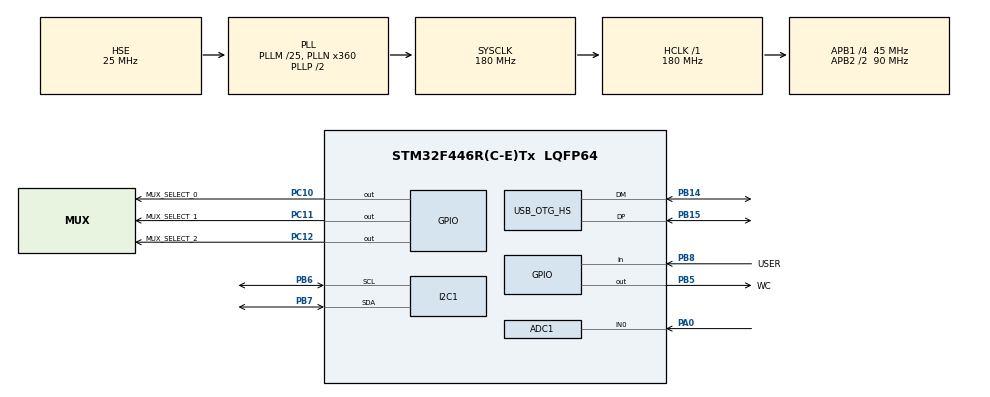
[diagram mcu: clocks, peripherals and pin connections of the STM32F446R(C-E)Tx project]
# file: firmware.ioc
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ADC1.Channel-0\#ChannelRegularConversion=ADC_CHANNEL_0
ADC1.NbrOfConversionFlag=1
ADC1.Rank-0\#ChannelRegularConversion=1
ADC1.SamplingTime-0\#ChannelRegularConversion=ADC_SAMPLETIME_3CYCLES
ADC1.master=1
Mcu.Family=STM32F4
Mcu.Name=STM32F446R(C-E)Tx
Mcu.Package=LQFP64
NVIC.ADC_IRQn=true\:0\:0\:false\:false\:true\:true\:true\:true
NVIC.OTG_HS_IRQn=true\:0\:0\:false\:false\:true\:true\:true\:true
NVIC.PriorityGroup=NVIC_PRIORITYGROUP_4
NVIC.TIM1_UP_TIM10_IRQn=true\:0\:0\:false\:false\:true\:true\:true\:true
PA0-WKUP.Signal=ADCx_IN0
PA13.Mode=Trace_Asynchronous_SW
PA13.Signal=SYS_JTMS-SWDIO
PA14.Mode=Trace_Asynchronous_SW
PA14.Signal=SYS_JTCK-SWCLK
PB14.Mode=Device_Only_FS
PB14.Signal=USB_OTG_HS_DM
PB15.Mode=Device_Only_FS
PB15.Signal=USB_OTG_HS_DP
PB3.Mode=Trace_Asynchronous_SW
PB3.Signal=SYS_JTDO-SWO
PB5.GPIO_Label=WC
PB5.GPIO_Speed=GPIO_SPEED_FREQ_HIGH
PB5.Signal=GPIO_Output
PB6.Mode=I2C
PB6.Signal=I2C1_SCL
PB7.Mode=I2C
PB7.Signal=I2C1_SDA
PB8.GPIO_Label=USER
PB8.Signal=GPIO_Input
PC10.GPIO_Label=MUX_SELECT_0
PC10.GPIO_Speed=GPIO_SPEED_FREQ_VERY_HIGH
PC10.Signal=GPIO_Output
PC11.GPIO_Label=MUX_SELECT_1
PC11.GPIO_Speed=GPIO_SPEED_FREQ_VERY_HIGH
PC11.Signal=GPIO_Output
PC12.GPIO_Label=MUX_SELECT_2
PC12.GPIO_Speed=GPIO_SPEED_FREQ_VERY_HIGH
PC12.Signal=GPIO_Output
PH0-OSC_IN.Mode=HSE-External-Oscillator
PH0-OSC_IN.Signal=RCC_OSC_IN
PH1-OSC_OUT.Mode=HSE-External-Oscillator
PH1-OSC_OUT.Signal=RCC_OSC_OUT
ProjectManager.HeapSize=0x200
ProjectManager.StackSize=0x400
ProjectManager.TargetToolchain=STM32CubeIDE
RCC.AHBFreq_Value=180000000
RCC.APB1CLKDivider=RCC_HCLK_DIV4
RCC.APB1Freq_Value=45000000
RCC.APB1TimFreq_Value=90000000
RCC.APB2CLKDivider=RCC_HCLK_DIV2
RCC.APB2Freq_Value=90000000
RCC.APB2TimFreq_Value=180000000
RCC.CortexFreq_Value=180000000
RCC.HCLKFreq_Value=180000000
RCC.PLLM=25
RCC.PLLN=360
RCC.PLLSAIM=25
RCC.PLLSAIP=RCC_PLLSAIP_DIV4
RCC.PLLSourceVirtual=RCC_PLLSOURCE_HSE
RCC.SYSCLKFreq_VALUE=180000000
RCC.SYSCLKSource=RCC_SYSCLKSOURCE_PLLCLK
RCC.USBCLockSelection=RCC_CLK48CLKSOURCE_PLLSAIP
RCC.USBFreq_Value=48000000
RCC.VCOOutputFreq_Value=360000000
SH.ADCx_IN0.0=ADC1_IN0,IN0
TIM10.Period=3600 - 1
TIM10.Prescaler=0
USB_OTG_HS.VirtualMode-Device_Only_FS=Device_Only_FS
VP_TIM10_VS_ClockSourceINT.Mode=Enable_Timer
board=custom

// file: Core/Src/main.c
/* USER CODE BEGIN Header */
/**
 ******************************************************************************
 * @file           : main.c
 * @brief          : Main program body
 ******************************************************************************
 * @attention
 *
 * Copyright (c) 2024 STMicroelectronics.
 * All rights reserved.
 *
 * This software is licensed under terms that can be found in the LICENSE file
 * in the root directory of this software component.
 * If no LICENSE file comes with this software, it is provided AS-IS.
 *
 ******************************************************************************
 */
/* USER CODE END Header */
#include "main.h"

/* USER CODE BEGIN Includes */

#include "firmware.h"

/* USER CODE END Includes */

ADC_HandleTypeDef hadc1;

I2C_HandleTypeDef hi2c1;

TIM_HandleTypeDef htim10;

PCD_HandleTypeDef hpcd_USB_OTG_HS;

void SystemClock_Config(void);
static void MX_GPIO_Init(void);
static void MX_ADC1_Init(void);
static void MX_I2C1_Init(void);
static void MX_TIM10_Init(void);
static void MX_USB_OTG_HS_PCD_Init(void);

int main(void) {

  /* MCU Configuration--------------------------------------------------------*/

  /* Reset of all peripherals, Initializes the Flash interface and the Systick.
   */
  HAL_Init();

  /* Configure the system clock */
  SystemClock_Config();

  /* Initialize all configured peripherals */
  MX_GPIO_Init();
  MX_ADC1_Init();
  MX_I2C1_Init();
  MX_TIM10_Init();
  MX_USB_OTG_HS_PCD_Init();
  /* USER CODE BEGIN 2 */

  firmware_init();

  /* USER CODE END 2 */

  /* Infinite loop */
  /* USER CODE BEGIN WHILE */
  while (1) {
    firmware_loop();
    /* USER CODE END WHILE */

  }
}

void SystemClock_Config(void) {
  RCC_OscInitTypeDef RCC_OscInitStruct = {0};
  RCC_ClkInitTypeDef RCC_ClkInitStruct = {0};

  /** Configure the main internal regulator output voltage
   */
  __HAL_RCC_PWR_CLK_ENABLE();
  __HAL_PWR_VOLTAGESCALING_CONFIG(PWR_REGULATOR_VOLTAGE_SCALE1);

  /** Initializes the RCC Oscillators according to the specified parameters
   * in the RCC_OscInitTypeDef structure.
   */
  RCC_OscInitStruct.OscillatorType = RCC_OSCILLATORTYPE_HSE;
  RCC_OscInitStruct.HSEState = RCC_HSE_ON;
  RCC_OscInitStruct.PLL.PLLState = RCC_PLL_ON;
  RCC_OscInitStruct.PLL.PLLSource = RCC_PLLSOURCE_HSE;
  RCC_OscInitStruct.PLL.PLLM = 25;
  RCC_OscInitStruct.PLL.PLLN = 360;
  RCC_OscInitStruct.PLL.PLLP = RCC_PLLP_DIV2;
  RCC_OscInitStruct.PLL.PLLQ = 2;
  RCC_OscInitStruct.PLL.PLLR = 2;
  if (HAL_RCC_OscConfig(&RCC_OscInitStruct) != HAL_OK) {
    Error_Handler();
  }

  /** Activate the Over-Drive mode
   */
  if (HAL_PWREx_EnableOverDrive() != HAL_OK) {
    Error_Handler();
  }

  /** Initializes the CPU, AHB and APB buses clocks
   */
  RCC_ClkInitStruct.ClockType = RCC_CLOCKTYPE_HCLK | RCC_CLOCKTYPE_SYSCLK |
                                RCC_CLOCKTYPE_PCLK1 | RCC_CLOCKTYPE_PCLK2;
  RCC_ClkInitStruct.SYSCLKSource = RCC_SYSCLKSOURCE_PLLCLK;
  RCC_ClkInitStruct.AHBCLKDivider = RCC_SYSCLK_DIV1;
  RCC_ClkInitStruct.APB1CLKDivider = RCC_HCLK_DIV4;
  RCC_ClkInitStruct.APB2CLKDivider = RCC_HCLK_DIV2;

  if (HAL_RCC_ClockConfig(&RCC_ClkInitStruct, FLASH_LATENCY_5) != HAL_OK) {
    Error_Handler();
  }
}

static void MX_ADC1_Init(void) {

  ADC_ChannelConfTypeDef sConfig = {0};

  /** Configure the global features of the ADC (Clock, Resolution, Data
   * Alignment and number of conversion)
   */
  hadc1.Instance = ADC1;
  hadc1.Init.ClockPrescaler = ADC_CLOCK_SYNC_PCLK_DIV4;
  hadc1.Init.Resolution = ADC_RESOLUTION_12B;
  hadc1.Init.ScanConvMode = DISABLE;
  hadc1.Init.ContinuousConvMode = DISABLE;
  hadc1.Init.DiscontinuousConvMode = DISABLE;
  hadc1.Init.ExternalTrigConvEdge = ADC_EXTERNALTRIGCONVEDGE_NONE;
  hadc1.Init.ExternalTrigConv = ADC_SOFTWARE_START;
  hadc1.Init.DataAlign = ADC_DATAALIGN_RIGHT;
  hadc1.Init.NbrOfConversion = 1;
  hadc1.Init.DMAContinuousRequests = DISABLE;
  hadc1.Init.EOCSelection = ADC_EOC_SINGLE_CONV;
  if (HAL_ADC_Init(&hadc1) != HAL_OK) {
    Error_Handler();
  }

  /** Configure for the selected ADC regular channel its corresponding rank in
   * the sequencer and its sample time.
   */
  sConfig.Channel = ADC_CHANNEL_0;
  sConfig.Rank = 1;
  sConfig.SamplingTime = ADC_SAMPLETIME_3CYCLES;
  if (HAL_ADC_ConfigChannel(&hadc1, &sConfig) != HAL_OK) {
    Error_Handler();
  }
}

static void MX_I2C1_Init(void) {

  hi2c1.Instance = I2C1;
  hi2c1.Init.ClockSpeed = 100000;
  hi2c1.Init.DutyCycle = I2C_DUTYCYCLE_2;
  hi2c1.Init.OwnAddress1 = 0;
  hi2c1.Init.AddressingMode = I2C_ADDRESSINGMODE_7BIT;
  hi2c1.Init.DualAddressMode = I2C_DUALADDRESS_DISABLE;
  hi2c1.Init.OwnAddress2 = 0;
  hi2c1.Init.GeneralCallMode = I2C_GENERALCALL_DISABLE;
  hi2c1.Init.NoStretchMode = I2C_NOSTRETCH_DISABLE;
  if (HAL_I2C_Init(&hi2c1) != HAL_OK) {
    Error_Handler();
  }
}

static void MX_TIM10_Init(void) {

  htim10.Instance = TIM10;
  htim10.Init.Prescaler = 0;
  htim10.Init.CounterMode = TIM_COUNTERMODE_UP;
  htim10.Init.Period = 3600 - 1;
  htim10.Init.ClockDivision = TIM_CLOCKDIVISION_DIV1;
  htim10.Init.AutoReloadPreload = TIM_AUTORELOAD_PRELOAD_DISABLE;
  if (HAL_TIM_Base_Init(&htim10) != HAL_OK) {
    Error_Handler();
  }
}

static void MX_USB_OTG_HS_PCD_Init(void) {

  hpcd_USB_OTG_HS.Instance = USB_OTG_HS;
  hpcd_USB_OTG_HS.Init.dev_endpoints = 8;
  hpcd_USB_OTG_HS.Init.speed = PCD_SPEED_FULL;
  hpcd_USB_OTG_HS.Init.dma_enable = DISABLE;
  hpcd_USB_OTG_HS.Init.phy_itface = USB_OTG_EMBEDDED_PHY;
  hpcd_USB_OTG_HS.Init.Sof_enable = DISABLE;
  hpcd_USB_OTG_HS.Init.low_power_enable = DISABLE;
  hpcd_USB_OTG_HS.Init.lpm_enable = DISABLE;
  hpcd_USB_OTG_HS.Init.vbus_sensing_enable = DISABLE;
  hpcd_USB_OTG_HS.Init.use_dedicated_ep1 = DISABLE;
  hpcd_USB_OTG_HS.Init.use_external_vbus = DISABLE;
  if (HAL_PCD_Init(&hpcd_USB_OTG_HS) != HAL_OK) {
    Error_Handler();
  }
}

static void MX_GPIO_Init(void) {
  GPIO_InitTypeDef GPIO_InitStruct = {0};

  /* GPIO Ports Clock Enable */
  __HAL_RCC_GPIOH_CLK_ENABLE();
  __HAL_RCC_GPIOA_CLK_ENABLE();
  __HAL_RCC_GPIOB_CLK_ENABLE();
  __HAL_RCC_GPIOC_CLK_ENABLE();

  /*Configure GPIO pin Output Level */
  HAL_GPIO_WritePin(GPIOC,
                    MUX_SELECT_0_Pin | MUX_SELECT_1_Pin | MUX_SELECT_2_Pin,
                    GPIO_PIN_RESET);

  /*Configure GPIO pin Output Level */
  HAL_GPIO_WritePin(WC_GPIO_Port, WC_Pin, GPIO_PIN_RESET);

  /*Configure GPIO pins : MUX_SELECT_0_Pin MUX_SELECT_1_Pin MUX_SELECT_2_Pin */
  GPIO_InitStruct.Pin = MUX_SELECT_0_Pin | MUX_SELECT_1_Pin | MUX_SELECT_2_Pin;
  GPIO_InitStruct.Mode = GPIO_MODE_OUTPUT_PP;
  GPIO_InitStruct.Pull = GPIO_NOPULL;
  GPIO_InitStruct.Speed = GPIO_SPEED_FREQ_VERY_HIGH;
  HAL_GPIO_Init(GPIOC, &GPIO_InitStruct);

  /*Configure GPIO pin : WC_Pin */
  GPIO_InitStruct.Pin = WC_Pin;
  GPIO_InitStruct.Mode = GPIO_MODE_OUTPUT_PP;
  GPIO_InitStruct.Pull = GPIO_NOPULL;
  GPIO_InitStruct.Speed = GPIO_SPEED_FREQ_HIGH;
  HAL_GPIO_Init(WC_GPIO_Port, &GPIO_InitStruct);

  /*Configure GPIO pin : USER_Pin */
  GPIO_InitStruct.Pin = USER_Pin;
  GPIO_InitStruct.Mode = GPIO_MODE_INPUT;
  GPIO_InitStruct.Pull = GPIO_NOPULL;
  HAL_GPIO_Init(USER_GPIO_Port, &GPIO_InitStruct);

}

void Error_Handler(void) {
  __disable_irq();
  while (1) {
  }
}

#ifdef USE_FULL_ASSERT
/**
 * @brief  Reports the name of the source file and the source line number
 *         where the assert_param error has occurred.
 * @param  file: pointer to the source file name
 * @param  line: assert_param error line source number
 * @retval None
 */
void assert_failed(uint8_t *file, uint32_t line) {
  /* USER CODE BEGIN 6 */
  /* User can add his own implementation to report the file name and line
     number, ex: printf("Wrong parameters value: file %s on line %d\r\n", file,
     line) */
  /* USER CODE END 6 */
}
#endif /* USE_FULL_ASSERT */
